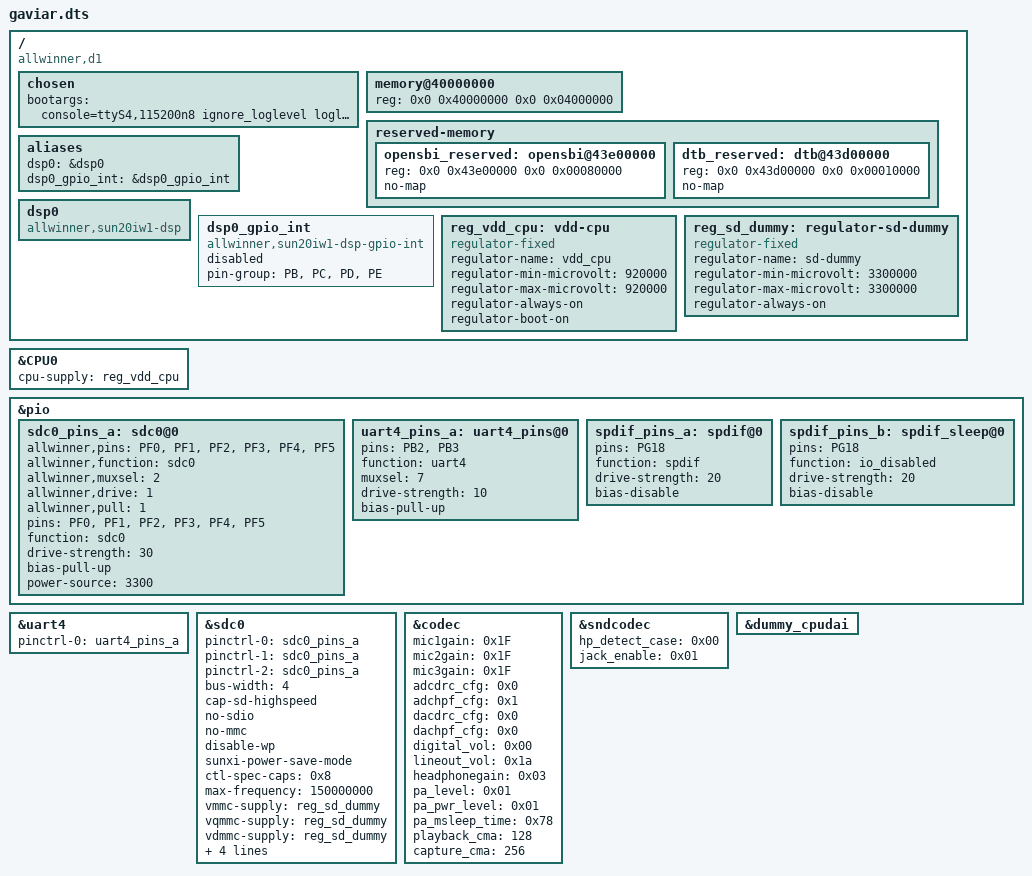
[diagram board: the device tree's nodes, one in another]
/dts-v1/;

#include "sun20iw1p1.dtsi"

/ {
    compatible = "allwinner,d1", "arm,sun20iw1p1", "allwinner,sun20iw1p1", "allwinner,gaviar";

    chosen {
        bootargs = "console=ttyS4,115200n8 ignore_loglevel loglevel=8 root=/dev/mmcblk0p1 rootwait ro rootfstype=vfat init=/mininit-syspart";
    };

    memory@40000000 {
        device_type = "memory";
        reg = <0x0 0x40000000 0x0 0x04000000>;
    };

    reserved-memory {
        #address-cells = <2>;
        #size-cells = <2>;
        ranges;

        opensbi_reserved: opensbi@43e00000 {
            reg = <0x0 0x43e00000 0x0 0x00080000>;
            no-map;
        };

        dtb_reserved: dtb@43d00000 {
            reg = <0x0 0x43d00000 0x0 0x00010000>;
            no-map;
        };
    };

    aliases {
        dsp0 = &dsp0;
        dsp0_gpio_int = &dsp0_gpio_int;
    };

    dsp0: dsp0 {
        compatible = "allwinner,sun20iw1-dsp";
        status = "okay";
    };

    dsp0_gpio_int: dsp0_gpio_int {
        compatible = "allwinner,sun20iw1-dsp-gpio-int";
        pin-group = "PB", "PC", "PD", "PE";
        status = "disabled";
    };

    reg_vdd_cpu: vdd-cpu {
        compatible = "regulator-fixed";
        regulator-name = "vdd_cpu";
        regulator-min-microvolt = <920000>;
        regulator-max-microvolt = <920000>;
        regulator-always-on;
        regulator-boot-on;
        status = "okay";
    };

    reg_sd_dummy: regulator-sd-dummy {
        compatible = "regulator-fixed";
        regulator-name = "sd-dummy";
        regulator-min-microvolt = <3300000>;
        regulator-max-microvolt = <3300000>;
        regulator-always-on;
    };
};

&CPU0 {
    cpu-supply = <&reg_vdd_cpu>;
};

&pio {
    sdc0_pins_a: sdc0@0 {
        allwinner,pins = "PF0", "PF1", "PF2", "PF3", "PF4", "PF5";
        allwinner,function = "sdc0";
        allwinner,muxsel = <2>;
        allwinner,drive = <1>;
        allwinner,pull = <1>;
        pins = "PF0", "PF1", "PF2", "PF3", "PF4", "PF5";
        function = "sdc0";
        drive-strength = <30>;
        bias-pull-up;
        power-source = <3300>;
    };

    uart4_pins_a: uart4_pins@0 {
        pins = "PB2", "PB3";
        function = "uart4";
        muxsel = <7>;
        drive-strength = <10>;
        bias-pull-up;
    };

    spdif_pins_a: spdif@0 {
        pins = "PG18";
        function = "spdif";
        drive-strength = <20>;
        bias-disable;
    };

    spdif_pins_b: spdif_sleep@0 {
        pins = "PG18";
        function = "io_disabled";
        drive-strength = <20>;
        bias-disable;
    };
};

&uart4 {
    pinctrl-names = "default";
    pinctrl-0 = <&uart4_pins_a>;
    status = "okay";
};

&sdc0 {
    pinctrl-names = "default", "mmc_1v8", "sleep";
    pinctrl-0 = <&sdc0_pins_a>;
    pinctrl-1 = <&sdc0_pins_a>;
    pinctrl-2 = <&sdc0_pins_a>;
    bus-width = <4>;
    cap-sd-highspeed;
    no-sdio;
    no-mmc;
    disable-wp;
    sunxi-power-save-mode;
    ctl-spec-caps = <0x8>;
    max-frequency = <150000000>;
    vmmc-supply = <&reg_sd_dummy>;
    vqmmc-supply = <&reg_sd_dummy>;
    vdmmc-supply = <&reg_sd_dummy>;
    vdmmc33sw-supply = <&reg_sd_dummy>;
    vqmmc33sw-supply = <&reg_sd_dummy>;
    vdmmc18sw-supply = <&reg_sd_dummy>;
    vqmmc18sw-supply = <&reg_sd_dummy>;
    status = "okay";
};

&codec {
    mic1gain = <0x1F>;
    mic2gain = <0x1F>;
    mic3gain = <0x1F>;
    adcdrc_cfg = <0x0>;
    adchpf_cfg = <0x1>;
    dacdrc_cfg = <0x0>;
    dachpf_cfg = <0x0>;
    digital_vol = <0x00>;
    lineout_vol = <0x1a>;
    headphonegain = <0x03>;
    pa_level = <0x01>;
    pa_pwr_level = <0x01>;
    pa_msleep_time = <0x78>;
    playback_cma = <128>;
    capture_cma = <256>;
    status = "okay";
};

&sndcodec {
    hp_detect_case = <0x00>;
    jack_enable = <0x01>;
    status = "okay";
};

&dummy_cpudai {
    status = "okay";
};
